# AT32F455xx_v2 register map
Vendor: Keil; Series: AT32F455; File version: 1.0
CPU: CM4 r0p1, little endian, no MPU, FPU, 4 interrupt priority bits
Registers are 32-bit, read-write, reset 0x0 unless marked. A register's access mark holds for its fields unless they carry their own. Offsets are from the block's base; [hi:lo] are bit positions.

## ADCCOM — ADC common area
Base 0x40012300
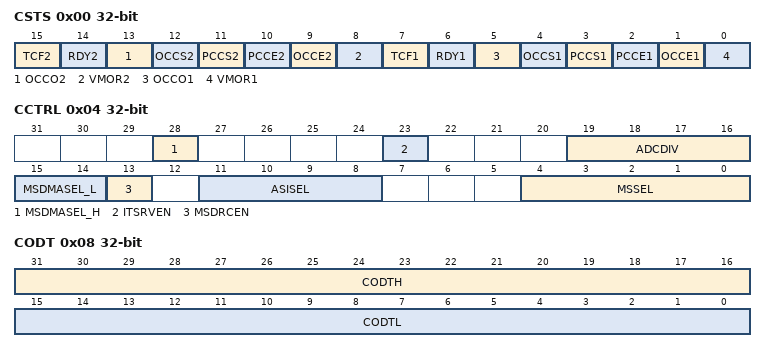
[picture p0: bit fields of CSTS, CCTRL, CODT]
0x00 CSTS ro — Common status register
  [15] TCF2 — Trigger convert fail flag of ADC2
  [14] RDY2 — ADC ready to conversion flag of ADC2
  [13] OCCO2 — Ordinary channel conversion overflow flag of ADC2
  [12] OCCS2 — Ordinary channel conversion start flag of ADC2
  [11] PCCS2 — Preempted channel conversion start flag of ADC2
  [10] PCCE2 — Preempted channels conversion end flag of ADC2
  [9] OCCE2 — Ordinary channels conversion end flag of ADC2
  [8] VMOR2 — Voltage monitoring out of range flag of ADC2
  [7] TCF1 — Trigger convert fail flag of ADC1
  [6] RDY1 — ADC ready to conversion flag of ADC1
  [5] OCCO1 — Ordinary channel conversion overflow flag of ADC1
  [4] OCCS1 — Ordinary channel conversion start flag of ADC1
  [3] PCCS1 — Preempted channel conversion start flag of ADC1
  [2] PCCE1 — Preempted channels conversion end flag of ADC1
  [1] OCCE1 — Ordinary channels conversion end flag of ADC1
  [0] VMOR1 — Voltage monitoring out of range flag of ADC1
0x04 CCTRL — Common control register
  [28] MSDMASEL_H — High bit of ordinary channel DMA transfer mode select for master slave mode
  [23] ITSRVEN — Internal temperature sensor and VINTRV enable
  [19:16] ADCDIV — ADC division
  [15:14] MSDMASEL_L — Low bit of ordinary channel DMA transfer mode select for master slave mode
  [13] MSDRCEN — Ordinary channel DMA request continuation enable for master slave mode
  [11:8] ASISEL — Adjacent ADC sampling interval select for ordinary shifting mode
  [4:0] MSSEL — Master slave mode select
0x08 CODT ro — Common Ordinary data register
  [31:16] CODTH — Ordinary conversion high halfword data for master slave mode
  [15:0] CODTL — Ordinary conversion low halfword data for master slave mode

## DAC — Digital to analog converter
Base 0x40007400
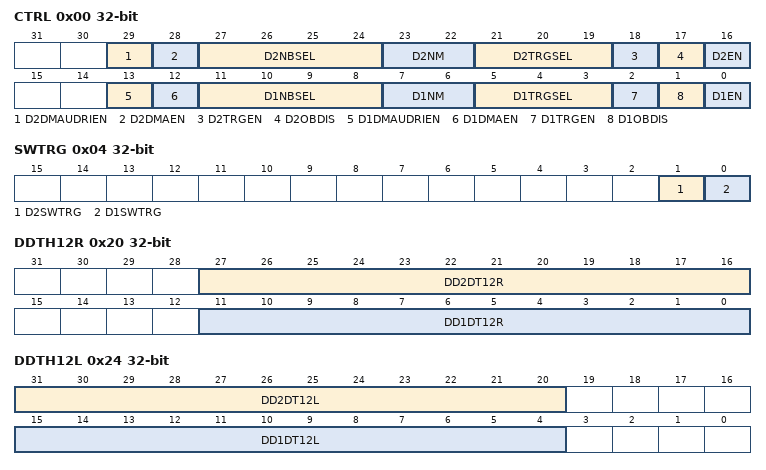
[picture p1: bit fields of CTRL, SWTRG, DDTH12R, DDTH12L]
0x00 CTRL — Control register (DAC_CTRL)
  [29] D2DMAUDRIEN — DAC2 DMA underrun interrupt enable
  [28] D2DMAEN — DAC2 DMA enable
  [27:24] D2NBSEL — DAC2 mask/amplitude selector
  [23:22] D2NM — DAC2 noise/triangle wave generation enable
  [21:19] D2TRGSEL — DAC2 trigger selection
  [18] D2TRGEN — DAC2 trigger enable
  [17] D2OBDIS — DAC2 output buffer disable
  [16] D2EN — DAC2 enable
  [13] D1DMAUDRIEN — DAC1 DMA underrun interrupt enable
  [12] D1DMAEN — DAC1 DMA enable
  [11:8] D1NBSEL — DAC1 mask/amplitude selector
  [7:6] D1NM — DAC1 noise/triangle wave generation enable
  [5:3] D1TRGSEL — DAC1 trigger selection
  [2] D1TRGEN — DAC1 trigger enable
  [1] D1OBDIS — DAC1 output buffer disable
  [0] D1EN — DAC1 enable
0x04 SWTRG wo — DAC software trigger register(DAC_SWTRIGR)
  [1] D2SWTRG — DAC2 software trigger
  [0] D1SWTRG — DAC1 software trigger
0x08 D1DTH12R — DAC1 12-bit right-aligned data holding register(DAC_D1DTH12R)
  [11:0] D1DT12R — DAC1 12-bit right-aligned data
0x0C D1DTH12L — DAC1 12-bit left aligned data holding register (DAC_D1DTH12L)
  [15:4] D1DT12L — DAC1 12-bit left-aligned data
0x10 D1DTH8R — DAC1 8-bit right aligned data holding register (DAC_D1DTH8R)
  [7:0] D1DT8R — DAC1 8-bit right-aligned data
0x14 D2DTH12R — DAC2 12-bit right aligned data holding register (DAC_D2DTH12R)
  [11:0] D2DT12R — DAC2 12-bit right-aligned data
0x18 D2DTH12L — DAC2 12-bit left aligned data holding register (DAC_D2DTH12L)
  [15:4] D2DT12L — DAC2 12-bit left-aligned data
0x1C D2DTH8R — DAC2 8-bit right-aligned data holding register (DAC_D2DTH8R)
  [7:0] D2DT8R — DAC2 8-bit right-aligned data
0x20 DDTH12R — Dual DAC 12-bit right-aligned data holding register (DAC_DDTH12R), Bits 31:28 Reserved, Bits 15:12 Reserved
  [27:16] DD2DT12R — DAC2 12-bit right-aligned data
  [11:0] DD1DT12R — DAC1 12-bit right-aligned data
0x24 DDTH12L — DUAL DAC 12-bit left aligned data holding register (DAC_DDTH12L), Bits 19:16 Reserved, Bits 3:0 Reserved
  [31:20] DD2DT12L — DAC2 12-bit right-aligned data
  [15:4] DD1DT12L — DAC1 12-bit left-aligned data
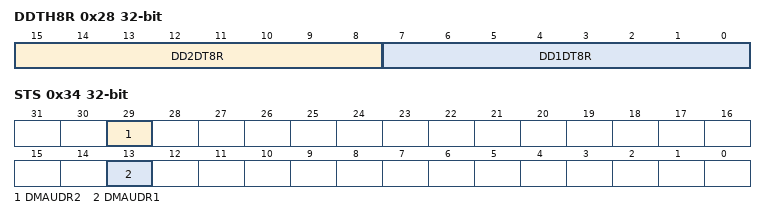
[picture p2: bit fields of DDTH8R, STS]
0x28 DDTH8R — DUAL DAC 8-bit right aligned data holding register (DAC_DDTH8R), Bits 31:16 Reserved
  [15:8] DD2DT8R — DAC2 8-bit right-aligned data
  [7:0] DD1DT8R — DAC1 8-bit right-aligned data
0x2C D1ODT ro — DAC1 data output register (DAC_D1ODT)
  [11:0] D1ODT — DAC1 data output
0x30 D2ODT ro — DAC2 data output register (DAC_D2ODT)
  [11:0] D2ODT — DAC2 data output
0x34 STS — DAC2 status register (DAC_STS)
  [29] DMAUDR2 — DAC2 DMA underrun flag
  [13] DMAUDR1 — DAC1 DMA underrun flag
